# Z20K14xM register map
Vendor: Zhixin Semiconductor; Series: Z20K14xM; File version: 0.1.0
CPU: CM4 r0p1, little endian, no MPU, FPU, 4 interrupt priority bits
Registers are 32-bit, read-write, reset 0x0 unless marked. A register's access mark holds for its fields unless they carry their own. Offsets are from the block's base; [hi:lo] are bit positions.

## SPI0
Base 0x4002C000
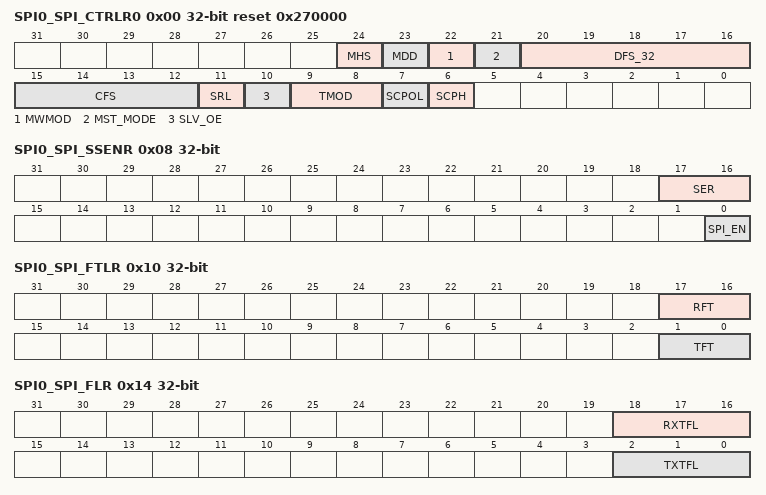
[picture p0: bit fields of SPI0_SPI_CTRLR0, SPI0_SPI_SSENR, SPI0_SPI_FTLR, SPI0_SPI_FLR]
0x00 SPI0_SPI_CTRLR0 reset 0x270000 — Control Register 0(SPI_CTRLR0)
  [24] MHS — Microwire Handshaking
  [23] MDD — Microwire Control
  [22] MWMOD — Microwire Transfer Mode
  [21] MST_MODE — Master mode enable
  [20:16] DFS_32 — Data Frame Size in 32-bit mode
  [15:12] CFS — Control Frame Size
  [11] SRL — Shift Register Loop
  [10] SLV_OE — Slave Output Enable.
  [9:8] TMOD — Transfer Mode
  [7] SCPOL — Serial Clock Polarity
  [6] SCPH — Serial Clock Phase
0x04 SPI0_SPI_CTRLR1 — Control Register 1(SPI_CTRLR1)
  [15:0] NDF — Number of Data Frames
0x08 SPI0_SPI_SSENR — SPI Enable Register(SPI_SSENR)
  [17:16] SER — Slave Select Enable Flag
  [0] SPI_EN — SPI enable trigger
0x0C SPI0_SPI_BAUDR — Baud Rate Select Register(SPI_BAUDR)
  [15:0] SCKDV — SPI Clock Divider
0x10 SPI0_SPI_FTLR — FIFO Threshold Level Register(SPI_FTLR)
  [17:16] RFT — Receive FIFO Threshold.
  [1:0] TFT — Transmit FIFO Threshold
0x14 SPI0_SPI_FLR ro — FIFO Level Register(SPI_FLR)
  [18:16] RXTFL — Receive FIFO Level
  [2:0] TXTFL — Transmit FIFO Level
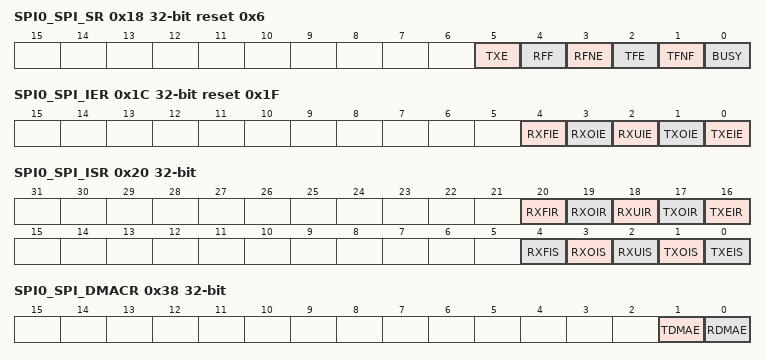
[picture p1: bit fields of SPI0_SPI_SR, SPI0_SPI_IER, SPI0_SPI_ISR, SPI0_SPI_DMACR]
0x18 SPI0_SPI_SR ro reset 0x6 — Status Register(SPI_SR)
  [5] TXE — Transmission Error
  [4] RFF — Receive FIFO Full
  [3] RFNE — Receive FIFO Not Empty
  [2] TFE — Transmit FIFO Empty
  [1] TFNF — Transmit FIFO Not Full
  [0] BUSY — SPI Busy Flag
0x1C SPI0_SPI_IER reset 0x1F — Interrupt Enable Register(SPI_IER)
  [4] RXFIE — Receive FIFO Full Interrupt Mask
  [3] RXOIE — Receive FIFO Overflow Interrupt Mask
  [2] RXUIE — Receive FIFO Underflow Interrupt Mask
  [1] TXOIE — Transmit FIFO Overflow Interrupt Mask
  [0] TXEIE — Transmit FIFO Empty Interrupt Mask
0x20 SPI0_SPI_ISR ro — Interrupt Status Register(SPI_ISR)
  [20] RXFIR — Receive FIFO Full Raw Interrupt Status
  [19] RXOIR — Receive FIFO Overflow Raw Interrupt Status
  [18] RXUIR — Receive FIFO Underflow Raw Interrupt Status
  [17] TXOIR — Transmit FIFO Overflow Raw Interrupt Status
  [16] TXEIR — Transmit FIFO Empty Raw Interrupt Status
  [4] RXFIS — Receive FIFO Full Interrupt Status
  [3] RXOIS — Receive FIFO Overflow Interrupt Status
  [2] RXUIS — Receive FIFO Underflow Interrupt Status
  [1] TXOIS — Transmit FIFO Overflow Interrupt Status
  [0] TXEIS — Transmit FIFO Empty Interrupt Status
0x24 SPI0_SPI_TXOICR ro — Transmit FIFO Overflow Interrupt Clear Register(SPI_TXOICR)
  [0] TXOICR — Clear Transmit FIFO Overflow Interrupt
0x28 SPI0_SPI_RXOICR ro — Receive FIFO Overflow Interrupt Clear Register(SPI_RXOICR)
  [0] RXOICR — Clear Receive FIFO Overflow Interrupt
0x2C SPI0_SPI_RXUICR ro — Receive FIFO Underflow Interrupt Clear Register(SPI_RXUICR)
  [0] RXUICR — Reserved
0x34 SPI0_SPI_ICR ro — Interrupt Clear Register(SPI_ICR)
  [0] ICR — Reserved
0x38 SPI0_SPI_DMACR — DMA Control Register(SPI_DMACR)
  [1] TDMAE — Transmit DMA Enable
  [0] RDMAE — Receive DMA Enable
0x3C SPI0_SPI_DMATDLR — DMA Transmit Data Level(SPI_DMATDLR)
  [1:0] DMATDL — Transmit Data Level
0x40 SPI0_SPI_DMARDLR — DMA Receive Data Level(SPI_DMARDLR)
  [1:0] DMARDL — Receive Data Level
0x44 SPI0_SPI_IDR ro — Identification Register(SPI_IDR)
  [31:0] IDCODE — Identification Code.
0x48 SPI0_SPI_VIDR ro — Version ID register(SPI_VIDR)
  [31:0] VID — SPI version ID
0x60 SPI0_SPI_DR_LOW — Data Register(SPI_DR_LOW)
  [31:0] DR — Data Register
0xEC SPI0_SPI_DR_HIGH — Data Register(SPI_DR_HIGH)
  [31:0] DR — Data Register

## SPI1
Base 0x4002D000
Registers as SPI0 (with SPI0 read as SPI1).

## SPI2
Base 0x40030000
Registers as SPI0 (with SPI0 read as SPI2).

## SPI3
Base 0x40031000
Registers as SPI0 (with SPI0 read as SPI3).
